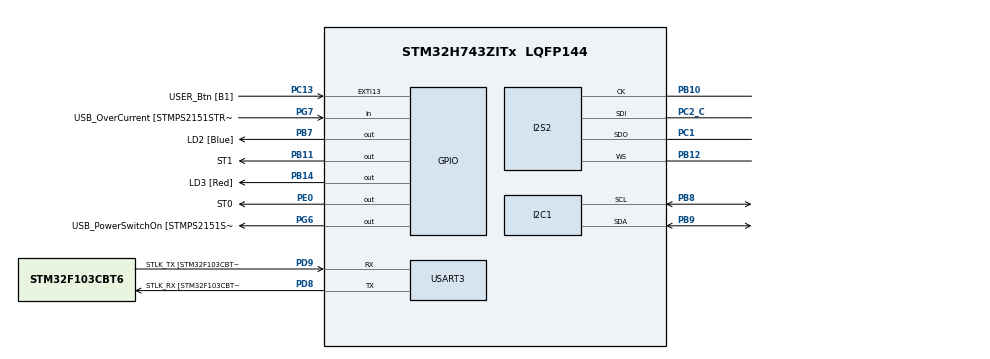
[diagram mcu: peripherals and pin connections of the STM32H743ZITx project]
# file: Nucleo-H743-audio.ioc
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CORTEX_M7.CPU_DCache=Enabled
CORTEX_M7.CPU_ICache=Enabled
Dma.Request0=USART3_RX
Dma.Request1=USART3_TX
Dma.Request2=SPI2_TX
Dma.Request3=SPI2_RX
Dma.SPI2_RX.3.Direction=DMA_PERIPH_TO_MEMORY
Dma.SPI2_RX.3.EventEnable=DISABLE
Dma.SPI2_RX.3.FIFOMode=DMA_FIFOMODE_DISABLE
Dma.SPI2_RX.3.Instance=DMA1_Stream3
Dma.SPI2_RX.3.MemDataAlignment=DMA_MDATAALIGN_WORD
Dma.SPI2_RX.3.MemInc=DMA_MINC_ENABLE
Dma.SPI2_RX.3.Mode=DMA_CIRCULAR
Dma.SPI2_RX.3.PeriphDataAlignment=DMA_PDATAALIGN_WORD
Dma.SPI2_RX.3.PeriphInc=DMA_PINC_DISABLE
Dma.SPI2_RX.3.Polarity=HAL_DMAMUX_REQ_GEN_RISING
Dma.SPI2_RX.3.Priority=DMA_PRIORITY_LOW
Dma.SPI2_RX.3.RequestNumber=1
Dma.SPI2_RX.3.SignalID=NONE
Dma.SPI2_RX.3.SyncEnable=DISABLE
Dma.SPI2_RX.3.SyncPolarity=HAL_DMAMUX_SYNC_NO_EVENT
Dma.SPI2_RX.3.SyncRequestNumber=1
Dma.SPI2_RX.3.SyncSignalID=NONE
Dma.SPI2_TX.2.Direction=DMA_MEMORY_TO_PERIPH
Dma.SPI2_TX.2.EventEnable=DISABLE
Dma.SPI2_TX.2.FIFOMode=DMA_FIFOMODE_DISABLE
Dma.SPI2_TX.2.Instance=DMA1_Stream2
Dma.SPI2_TX.2.MemDataAlignment=DMA_MDATAALIGN_WORD
Dma.SPI2_TX.2.MemInc=DMA_MINC_ENABLE
Dma.SPI2_TX.2.Mode=DMA_NORMAL
Dma.SPI2_TX.2.PeriphDataAlignment=DMA_PDATAALIGN_WORD
Dma.SPI2_TX.2.PeriphInc=DMA_PINC_DISABLE
Dma.SPI2_TX.2.Polarity=HAL_DMAMUX_REQ_GEN_RISING
Dma.SPI2_TX.2.Priority=DMA_PRIORITY_LOW
Dma.SPI2_TX.2.RequestNumber=1
Dma.SPI2_TX.2.SignalID=NONE
Dma.SPI2_TX.2.SyncEnable=DISABLE
Dma.SPI2_TX.2.SyncPolarity=HAL_DMAMUX_SYNC_NO_EVENT
Dma.SPI2_TX.2.SyncRequestNumber=1
Dma.SPI2_TX.2.SyncSignalID=NONE
Dma.USART3_RX.0.Direction=DMA_PERIPH_TO_MEMORY
Dma.USART3_RX.0.EventEnable=DISABLE
Dma.USART3_RX.0.FIFOMode=DMA_FIFOMODE_DISABLE
Dma.USART3_RX.0.Instance=DMA1_Stream0
Dma.USART3_RX.0.MemDataAlignment=DMA_MDATAALIGN_BYTE
Dma.USART3_RX.0.MemInc=DMA_MINC_ENABLE
Dma.USART3_RX.0.Mode=DMA_NORMAL
Dma.USART3_RX.0.PeriphDataAlignment=DMA_PDATAALIGN_BYTE
Dma.USART3_RX.0.PeriphInc=DMA_PINC_DISABLE
Dma.USART3_RX.0.Polarity=HAL_DMAMUX_REQ_GEN_RISING
Dma.USART3_RX.0.Priority=DMA_PRIORITY_LOW
Dma.USART3_RX.0.RequestNumber=1
Dma.USART3_RX.0.SignalID=NONE
Dma.USART3_RX.0.SyncEnable=DISABLE
Dma.USART3_RX.0.SyncPolarity=HAL_DMAMUX_SYNC_NO_EVENT
Dma.USART3_RX.0.SyncRequestNumber=1
Dma.USART3_RX.0.SyncSignalID=NONE
Dma.USART3_TX.1.Direction=DMA_MEMORY_TO_PERIPH
Dma.USART3_TX.1.EventEnable=DISABLE
Dma.USART3_TX.1.FIFOMode=DMA_FIFOMODE_DISABLE
Dma.USART3_TX.1.Instance=DMA1_Stream1
Dma.USART3_TX.1.MemDataAlignment=DMA_MDATAALIGN_BYTE
Dma.USART3_TX.1.MemInc=DMA_MINC_ENABLE
Dma.USART3_TX.1.Mode=DMA_NORMAL
Dma.USART3_TX.1.PeriphDataAlignment=DMA_PDATAALIGN_BYTE
Dma.USART3_TX.1.PeriphInc=DMA_PINC_DISABLE
Dma.USART3_TX.1.Polarity=HAL_DMAMUX_REQ_GEN_RISING
Dma.USART3_TX.1.Priority=DMA_PRIORITY_LOW
Dma.USART3_TX.1.RequestNumber=1
Dma.USART3_TX.1.SignalID=NONE
Dma.USART3_TX.1.SyncEnable=DISABLE
Dma.USART3_TX.1.SyncPolarity=HAL_DMAMUX_SYNC_NO_EVENT
Dma.USART3_TX.1.SyncRequestNumber=1
Dma.USART3_TX.1.SyncSignalID=NONE
FREERTOS.Tasks01=defaultTask,0,256,StartDefaultTask,Default,NULL,Dynamic,NULL,NULL
FREERTOS.configMINIMAL_STACK_SIZE=256
FREERTOS.configTOTAL_HEAP_SIZE=32768
I2C1.Timing=0x307075B1
I2S2.AudioFreq=I2S_AUDIOFREQ_48K
I2S2.DataFormat=I2S_DATAFORMAT_32B
I2S2.ErrorAudioFreq=0.15 %
I2S2.Instance=SPI$Index
I2S2.RealAudioFreq=48.076 KHz
Mcu.Family=STM32H7
Mcu.Name=STM32H743ZITx
Mcu.Package=LQFP144
NVIC.DMA1_Stream0_IRQn=true\:5\:0\:false\:false\:true\:true\:false\:true
NVIC.DMA1_Stream1_IRQn=true\:5\:0\:false\:false\:true\:true\:false\:true
NVIC.DMA1_Stream2_IRQn=true\:5\:0\:false\:false\:true\:true\:false\:true
NVIC.DMA1_Stream3_IRQn=true\:5\:0\:false\:false\:true\:true\:false\:true
NVIC.I2C1_ER_IRQn=true\:5\:0\:false\:false\:true\:true\:true\:true
NVIC.I2C1_EV_IRQn=true\:5\:0\:false\:false\:true\:true\:true\:true
NVIC.PriorityGroup=NVIC_PRIORITYGROUP_4
NVIC.SPI2_IRQn=true\:5\:0\:false\:false\:true\:true\:true\:true
NVIC.TIM17_IRQn=true\:0\:0\:false\:false\:true\:false\:false\:true
NVIC.TimeBase=TIM17_IRQn
NVIC.TimeBaseIP=TIM17
NVIC.USART3_IRQn=true\:5\:0\:false\:false\:true\:true\:true\:true
PB10.Mode=Full_Duplex_Master
PB10.Signal=I2S2_CK
PB11.GPIO_Label=ST1
PB11.Signal=GPIO_Output
PB12.Mode=Full_Duplex_Master
PB12.Signal=I2S2_WS
PB14.GPIO_Label=LD3 [Red]
PB14.Signal=GPIO_Output
PB7.GPIO_Label=LD2 [Blue]
PB7.Signal=GPIO_Output
PB8.Mode=I2C
PB8.Signal=I2C1_SCL
PB9.Mode=I2C
PB9.Signal=I2C1_SDA
PC1.Mode=Full_Duplex_Master
PC1.Signal=I2S2_SDO
PC13.GPIO_Label=USER_Btn [B1]
PC13.Signal=GPXTI13
PC14-OSC32_IN\ (OSC32_IN).Mode=LSE-External-Oscillator
PC14-OSC32_IN\ (OSC32_IN).Signal=RCC_OSC32_IN
PC15-OSC32_OUT\ (OSC32_OUT).Mode=LSE-External-Oscillator
PC15-OSC32_OUT\ (OSC32_OUT).Signal=RCC_OSC32_OUT
PC2_C.Mode=Full_Duplex_Master
PC2_C.Signal=I2S2_SDI
PD8.GPIO_Label=STLK_RX [STM32F103CBT6_PA3]
PD8.Mode=Asynchronous
PD8.Signal=USART3_TX
PD9.GPIO_Label=STLK_TX [STM32F103CBT6_PA2]
PD9.Mode=Asynchronous
PD9.Signal=USART3_RX
PE0.GPIO_Label=ST0
PE0.Signal=GPIO_Output
PG6.GPIO_Label=USB_PowerSwitchOn [STMPS2151STR_EN]
PG6.Signal=GPIO_Output
PG7.GPIO_Label=USB_OverCurrent [STMPS2151STR_FAULT]
PG7.Signal=GPIO_Input
PH0-OSC_IN\ (PH0).GPIO_Label=MCO
PH0-OSC_IN\ (PH0).Mode=HSE-External-Clock-Source
PH0-OSC_IN\ (PH0).Signal=RCC_OSC_IN
PH1-OSC_OUT\ (PH1).Mode=HSE-External-Clock-Source
PH1-OSC_OUT\ (PH1).Signal=RCC_OSC_OUT
ProjectManager.HeapSize=0x200
ProjectManager.StackSize=0x400
ProjectManager.TargetToolchain=STM32CubeIDE
RCC.48MHZClocksFreq_Value=24000000
RCC.ADCFreq_Value=16125000
RCC.AHBFreq_Value=216000000
RCC.APB1CLKDivider=RCC_HCLK_DIV4
RCC.APB1Freq_Value=120000000
RCC.APB1TimFreq_Value=108000000
RCC.APB2CLKDivider=RCC_HCLK_DIV2
RCC.APB2Freq_Value=120000000
RCC.APB2TimFreq_Value=216000000
RCC.APB3Freq_Value=120000000
RCC.APB4Freq_Value=120000000
RCC.CortexFreq_Value=240000000
RCC.D1PPRE=RCC_APB3_DIV2
RCC.D2PPRE1=RCC_APB1_DIV2
RCC.D2PPRE2=RCC_APB2_DIV2
RCC.D3PPRE=RCC_APB4_DIV2
RCC.DIVM1=1
RCC.DIVN1=60
RCC.DIVQ1=4
RCC.HCLKFreq_Value=240000000
RCC.HSE_VALUE=8000000
RCC.HSI_VALUE=64000000
RCC.PLLFRACN=0
RCC.PLLM=25
RCC.PLLMUL=RCC_PLL_MUL9
RCC.PLLN=432
RCC.PLLQ=9
RCC.PLLSourceVirtual=RCC_PLLSOURCE_HSE
RCC.PRESCALERUSB=RCC_USBCLKSOURCE_PLL_DIV1_5
RCC.PWR_Regulator_Voltage_Scale=PWR_REGULATOR_VOLTAGE_SCALE1
RCC.SYSCLKFreq_VALUE=240000000
RCC.SYSCLKSource=RCC_SYSCLKSOURCE_PLLCLK
RCC.SYSCLKSourceVirtual=RCC_SYSCLKSOURCE_PLLCLK
RCC.USBFreq_Value=120000000
RCC.VCOOutputFreq_Value=432000000
USART3.VirtualMode-Asynchronous=VM_ASYNC
VP_FREERTOS_VS_CMSIS_V1.Mode=CMSIS_V1
VP_SYS_VS_tim17.Mode=TIM17
board=NUCLEO-H743ZI

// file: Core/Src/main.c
/* USER CODE BEGIN Header */
/**
 ******************************************************************************
 * @file           : main.c
 * @brief          : Main program body
 ******************************************************************************
 * @attention
 *
 * <h2><center>&copy; Copyright (c) 2020 STMicroelectronics.
 * All rights reserved.</center></h2>
 *
 * This software component is licensed by ST under BSD 3-Clause license,
 * the "License"; You may not use this file except in compliance with the
 * License. You may obtain a copy of the License at:
 *                        opensource.org/licenses/BSD-3-Clause
 *
 ******************************************************************************
 */
/* USER CODE END Header */

#include "main.h"
#include "cmsis_os.h"

/* USER CODE BEGIN Includes */
#include "murasaki_platform.hpp"

/* USER CODE END Includes */

I2C_HandleTypeDef hi2c1;

I2S_HandleTypeDef hi2s2;
DMA_HandleTypeDef hdma_spi2_tx;
DMA_HandleTypeDef hdma_spi2_rx;

UART_HandleTypeDef huart3;
DMA_HandleTypeDef hdma_usart3_rx;
DMA_HandleTypeDef hdma_usart3_tx;

osThreadId defaultTaskHandle;

void SystemClock_Config(void);
static void MX_GPIO_Init(void);
static void MX_DMA_Init(void);
static void MX_USART3_UART_Init(void);
static void MX_I2C1_Init(void);
static void MX_I2S2_Init(void);
void StartDefaultTask(void const * argument);

int main(void)
{

  /* Enable I-Cache---------------------------------------------------------*/
  SCB_EnableICache();

  /* Enable D-Cache---------------------------------------------------------*/
  SCB_EnableDCache();

  /* MCU Configuration--------------------------------------------------------*/

  /* Reset of all peripherals, Initializes the Flash interface and the Systick. */
  HAL_Init();

  /* Configure the system clock */
  SystemClock_Config();

  /* USER CODE BEGIN SysInit */
    __HAL_RCC_SPI1_CLK_ENABLE();
    SET_BIT(SPI1->CFG2, SPI_CFG2_IOSWP);
  /* USER CODE END SysInit */

  /* Initialize all configured peripherals */
  MX_GPIO_Init();
  MX_DMA_Init();
  MX_USART3_UART_Init();
  MX_I2C1_Init();
  MX_I2S2_Init();

  /* Create the thread(s) */
  /* definition and creation of defaultTask */
  osThreadDef(defaultTask, StartDefaultTask, osPriorityNormal, 0, 256);
  defaultTaskHandle = osThreadCreate(osThread(defaultTask), NULL);

  /* Start scheduler */
  osKernelStart();

  /* We should never get here as control is now taken by the scheduler */

  /* Infinite loop */
    while (1)
    {

    }
}

void SystemClock_Config(void)
{
  RCC_OscInitTypeDef RCC_OscInitStruct = {0};
  RCC_ClkInitTypeDef RCC_ClkInitStruct = {0};
  RCC_PeriphCLKInitTypeDef PeriphClkInitStruct = {0};

  /** Supply configuration update enable
  */
  HAL_PWREx_ConfigSupply(PWR_LDO_SUPPLY);
  /** Configure the main internal regulator output voltage
  */
  __HAL_PWR_VOLTAGESCALING_CONFIG(PWR_REGULATOR_VOLTAGE_SCALE1);

  while(!__HAL_PWR_GET_FLAG(PWR_FLAG_VOSRDY)) {}
  /** Initializes the CPU, AHB and APB busses clocks
  */
  RCC_OscInitStruct.OscillatorType = RCC_OSCILLATORTYPE_HSE;
  RCC_OscInitStruct.HSEState = RCC_HSE_BYPASS;
  RCC_OscInitStruct.PLL.PLLState = RCC_PLL_ON;
  RCC_OscInitStruct.PLL.PLLSource = RCC_PLLSOURCE_HSE;
  RCC_OscInitStruct.PLL.PLLM = 1;
  RCC_OscInitStruct.PLL.PLLN = 60;
  RCC_OscInitStruct.PLL.PLLP = 2;
  RCC_OscInitStruct.PLL.PLLQ = 4;
  RCC_OscInitStruct.PLL.PLLR = 2;
  RCC_OscInitStruct.PLL.PLLRGE = RCC_PLL1VCIRANGE_3;
  RCC_OscInitStruct.PLL.PLLVCOSEL = RCC_PLL1VCOWIDE;
  RCC_OscInitStruct.PLL.PLLFRACN = 0;
  if (HAL_RCC_OscConfig(&RCC_OscInitStruct) != HAL_OK)
  {
    Error_Handler();
  }
  /** Initializes the CPU, AHB and APB busses clocks
  */
  RCC_ClkInitStruct.ClockType = RCC_CLOCKTYPE_HCLK|RCC_CLOCKTYPE_SYSCLK
                              |RCC_CLOCKTYPE_PCLK1|RCC_CLOCKTYPE_PCLK2
                              |RCC_CLOCKTYPE_D3PCLK1|RCC_CLOCKTYPE_D1PCLK1;
  RCC_ClkInitStruct.SYSCLKSource = RCC_SYSCLKSOURCE_PLLCLK;
  RCC_ClkInitStruct.SYSCLKDivider = RCC_SYSCLK_DIV1;
  RCC_ClkInitStruct.AHBCLKDivider = RCC_HCLK_DIV1;
  RCC_ClkInitStruct.APB3CLKDivider = RCC_APB3_DIV2;
  RCC_ClkInitStruct.APB1CLKDivider = RCC_APB1_DIV2;
  RCC_ClkInitStruct.APB2CLKDivider = RCC_APB2_DIV2;
  RCC_ClkInitStruct.APB4CLKDivider = RCC_APB4_DIV2;

  if (HAL_RCC_ClockConfig(&RCC_ClkInitStruct, FLASH_LATENCY_4) != HAL_OK)
  {
    Error_Handler();
  }
  PeriphClkInitStruct.PeriphClockSelection = RCC_PERIPHCLK_USART3|RCC_PERIPHCLK_SPI2
                              |RCC_PERIPHCLK_I2C1;
  PeriphClkInitStruct.Spi123ClockSelection = RCC_SPI123CLKSOURCE_PLL;
  PeriphClkInitStruct.Usart234578ClockSelection = RCC_USART234578CLKSOURCE_D2PCLK1;
  PeriphClkInitStruct.I2c123ClockSelection = RCC_I2C123CLKSOURCE_D2PCLK1;
  if (HAL_RCCEx_PeriphCLKConfig(&PeriphClkInitStruct) != HAL_OK)
  {
    Error_Handler();
  }
}

static void MX_I2C1_Init(void)
{

  hi2c1.Instance = I2C1;
  hi2c1.Init.Timing = 0x307075B1;
  hi2c1.Init.OwnAddress1 = 0;
  hi2c1.Init.AddressingMode = I2C_ADDRESSINGMODE_7BIT;
  hi2c1.Init.DualAddressMode = I2C_DUALADDRESS_DISABLE;
  hi2c1.Init.OwnAddress2 = 0;
  hi2c1.Init.OwnAddress2Masks = I2C_OA2_NOMASK;
  hi2c1.Init.GeneralCallMode = I2C_GENERALCALL_DISABLE;
  hi2c1.Init.NoStretchMode = I2C_NOSTRETCH_DISABLE;
  if (HAL_I2C_Init(&hi2c1) != HAL_OK)
  {
    Error_Handler();
  }
  /** Configure Analogue filter
  */
  if (HAL_I2CEx_ConfigAnalogFilter(&hi2c1, I2C_ANALOGFILTER_ENABLE) != HAL_OK)
  {
    Error_Handler();
  }
  /** Configure Digital filter
  */
  if (HAL_I2CEx_ConfigDigitalFilter(&hi2c1, 0) != HAL_OK)
  {
    Error_Handler();
  }

}

static void MX_I2S2_Init(void)
{

  hi2s2.Instance = SPI2;
  hi2s2.Init.Mode = I2S_MODE_MASTER_FULLDUPLEX;
  hi2s2.Init.Standard = I2S_STANDARD_PHILIPS;
  hi2s2.Init.DataFormat = I2S_DATAFORMAT_32B;
  hi2s2.Init.MCLKOutput = I2S_MCLKOUTPUT_DISABLE;
  hi2s2.Init.AudioFreq = I2S_AUDIOFREQ_48K;
  hi2s2.Init.CPOL = I2S_CPOL_LOW;
  hi2s2.Init.FirstBit = I2S_FIRSTBIT_MSB;
  hi2s2.Init.WSInversion = I2S_WS_INVERSION_DISABLE;
  hi2s2.Init.Data24BitAlignment = I2S_DATA_24BIT_ALIGNMENT_RIGHT;
  hi2s2.Init.MasterKeepIOState = I2S_MASTER_KEEP_IO_STATE_DISABLE;
  if (HAL_I2S_Init(&hi2s2) != HAL_OK)
  {
    Error_Handler();
  }

}

static void MX_USART3_UART_Init(void)
{

  huart3.Instance = USART3;
  huart3.Init.BaudRate = 115200;
  huart3.Init.WordLength = UART_WORDLENGTH_8B;
  huart3.Init.StopBits = UART_STOPBITS_1;
  huart3.Init.Parity = UART_PARITY_NONE;
  huart3.Init.Mode = UART_MODE_TX_RX;
  huart3.Init.HwFlowCtl = UART_HWCONTROL_NONE;
  huart3.Init.OverSampling = UART_OVERSAMPLING_16;
  huart3.Init.OneBitSampling = UART_ONE_BIT_SAMPLE_DISABLE;
  huart3.Init.ClockPrescaler = UART_PRESCALER_DIV1;
  huart3.AdvancedInit.AdvFeatureInit = UART_ADVFEATURE_NO_INIT;
  if (HAL_UART_Init(&huart3) != HAL_OK)
  {
    Error_Handler();
  }
  if (HAL_UARTEx_SetTxFifoThreshold(&huart3, UART_TXFIFO_THRESHOLD_1_8) != HAL_OK)
  {
    Error_Handler();
  }
  if (HAL_UARTEx_SetRxFifoThreshold(&huart3, UART_RXFIFO_THRESHOLD_1_8) != HAL_OK)
  {
    Error_Handler();
  }
  if (HAL_UARTEx_DisableFifoMode(&huart3) != HAL_OK)
  {
    Error_Handler();
  }

}

static void MX_DMA_Init(void)
{

  /* DMA controller clock enable */
  __HAL_RCC_DMA1_CLK_ENABLE();

  /* DMA interrupt init */
  /* DMA1_Stream0_IRQn interrupt configuration */
  HAL_NVIC_SetPriority(DMA1_Stream0_IRQn, 5, 0);
  HAL_NVIC_EnableIRQ(DMA1_Stream0_IRQn);
  /* DMA1_Stream1_IRQn interrupt configuration */
  HAL_NVIC_SetPriority(DMA1_Stream1_IRQn, 5, 0);
  HAL_NVIC_EnableIRQ(DMA1_Stream1_IRQn);
  /* DMA1_Stream2_IRQn interrupt configuration */
  HAL_NVIC_SetPriority(DMA1_Stream2_IRQn, 5, 0);
  HAL_NVIC_EnableIRQ(DMA1_Stream2_IRQn);
  /* DMA1_Stream3_IRQn interrupt configuration */
  HAL_NVIC_SetPriority(DMA1_Stream3_IRQn, 5, 0);
  HAL_NVIC_EnableIRQ(DMA1_Stream3_IRQn);

}

static void MX_GPIO_Init(void)
{
  GPIO_InitTypeDef GPIO_InitStruct = {0};

  /* GPIO Ports Clock Enable */
  __HAL_RCC_GPIOE_CLK_ENABLE();
  __HAL_RCC_GPIOC_CLK_ENABLE();
  __HAL_RCC_GPIOF_CLK_ENABLE();
  __HAL_RCC_GPIOH_CLK_ENABLE();
  __HAL_RCC_GPIOA_CLK_ENABLE();
  __HAL_RCC_GPIOB_CLK_ENABLE();
  __HAL_RCC_GPIOG_CLK_ENABLE();
  __HAL_RCC_GPIOD_CLK_ENABLE();

  /*Configure GPIO pin Output Level */
  HAL_GPIO_WritePin(GPIOB, ST1_Pin|LD3_Pin|LD2_Pin, GPIO_PIN_RESET);

  /*Configure GPIO pin Output Level */
  HAL_GPIO_WritePin(USB_PowerSwitchOn_GPIO_Port, USB_PowerSwitchOn_Pin, GPIO_PIN_RESET);

  /*Configure GPIO pin Output Level */
  HAL_GPIO_WritePin(ST0_GPIO_Port, ST0_Pin, GPIO_PIN_RESET);

  /*Configure GPIO pins : PE2 PE3 PE4 PE5
                           PE6 PE7 PE8 PE9
                           PE10 PE11 PE12 PE13
                           PE14 PE15 PE1 */
  GPIO_InitStruct.Pin = GPIO_PIN_2|GPIO_PIN_3|GPIO_PIN_4|GPIO_PIN_5
                          |GPIO_PIN_6|GPIO_PIN_7|GPIO_PIN_8|GPIO_PIN_9
                          |GPIO_PIN_10|GPIO_PIN_11|GPIO_PIN_12|GPIO_PIN_13
                          |GPIO_PIN_14|GPIO_PIN_15|GPIO_PIN_1;
  GPIO_InitStruct.Mode = GPIO_MODE_ANALOG;
  GPIO_InitStruct.Pull = GPIO_NOPULL;
  HAL_GPIO_Init(GPIOE, &GPIO_InitStruct);

  /*Configure GPIO pin : USER_Btn_Pin */
  GPIO_InitStruct.Pin = USER_Btn_Pin;
  GPIO_InitStruct.Mode = GPIO_MODE_IT_RISING;
  GPIO_InitStruct.Pull = GPIO_NOPULL;
  HAL_GPIO_Init(USER_Btn_GPIO_Port, &GPIO_InitStruct);

  /*Configure GPIO pins : PF0 PF1 PF2 PF3
                           PF4 PF5 PF6 PF7
                           PF8 PF9 PF10 PF11
                           PF12 PF13 PF14 PF15 */
  GPIO_InitStruct.Pin = GPIO_PIN_0|GPIO_PIN_1|GPIO_PIN_2|GPIO_PIN_3
                          |GPIO_PIN_4|GPIO_PIN_5|GPIO_PIN_6|GPIO_PIN_7
                          |GPIO_PIN_8|GPIO_PIN_9|GPIO_PIN_10|GPIO_PIN_11
                          |GPIO_PIN_12|GPIO_PIN_13|GPIO_PIN_14|GPIO_PIN_15;
  GPIO_InitStruct.Mode = GPIO_MODE_ANALOG;
  GPIO_InitStruct.Pull = GPIO_NOPULL;
  HAL_GPIO_Init(GPIOF, &GPIO_InitStruct);

  /*Configure GPIO pins : PC0 PC3 PC4 PC5
                           PC6 PC7 PC8 PC9
                           PC10 PC11 PC12 */
  GPIO_InitStruct.Pin = GPIO_PIN_0|GPIO_PIN_3|GPIO_PIN_4|GPIO_PIN_5
                          |GPIO_PIN_6|GPIO_PIN_7|GPIO_PIN_8|GPIO_PIN_9
                          |GPIO_PIN_10|GPIO_PIN_11|GPIO_PIN_12;
  GPIO_InitStruct.Mode = GPIO_MODE_ANALOG;
  GPIO_InitStruct.Pull = GPIO_NOPULL;
  HAL_GPIO_Init(GPIOC, &GPIO_InitStruct);

  /*Configure GPIO pins : PA0 PA1 PA2 PA3
                           PA4 PA5 PA6 PA7
                           PA8 PA9 PA10 PA11
                           PA12 PA13 PA14 PA15 */
  GPIO_InitStruct.Pin = GPIO_PIN_0|GPIO_PIN_1|GPIO_PIN_2|GPIO_PIN_3
                          |GPIO_PIN_4|GPIO_PIN_5|GPIO_PIN_6|GPIO_PIN_7
                          |GPIO_PIN_8|GPIO_PIN_9|GPIO_PIN_10|GPIO_PIN_11
                          |GPIO_PIN_12|GPIO_PIN_13|GPIO_PIN_14|GPIO_PIN_15;
  GPIO_InitStruct.Mode = GPIO_MODE_ANALOG;
  GPIO_InitStruct.Pull = GPIO_NOPULL;
  HAL_GPIO_Init(GPIOA, &GPIO_InitStruct);

  /*Configure GPIO pins : PB0 PB1 PB2 PB13
                           PB15 PB3 PB4 PB5
                           PB6 */
  GPIO_InitStruct.Pin = GPIO_PIN_0|GPIO_PIN_1|GPIO_PIN_2|GPIO_PIN_13
                          |GPIO_PIN_15|GPIO_PIN_3|GPIO_PIN_4|GPIO_PIN_5
                          |GPIO_PIN_6;
  GPIO_InitStruct.Mode = GPIO_MODE_ANALOG;
  GPIO_InitStruct.Pull = GPIO_NOPULL;
  HAL_GPIO_Init(GPIOB, &GPIO_InitStruct);

  /*Configure GPIO pins : PG0 PG1 PG2 PG3
                           PG4 PG5 PG8 PG9
                           PG10 PG11 PG12 PG13
                           PG14 PG15 */
  GPIO_InitStruct.Pin = GPIO_PIN_0|GPIO_PIN_1|GPIO_PIN_2|GPIO_PIN_3
                          |GPIO_PIN_4|GPIO_PIN_5|GPIO_PIN_8|GPIO_PIN_9
                          |GPIO_PIN_10|GPIO_PIN_11|GPIO_PIN_12|GPIO_PIN_13
                          |GPIO_PIN_14|GPIO_PIN_15;
  GPIO_InitStruct.Mode = GPIO_MODE_ANALOG;
  GPIO_InitStruct.Pull = GPIO_NOPULL;
  HAL_GPIO_Init(GPIOG, &GPIO_InitStruct);

  /*Configure GPIO pins : ST1_Pin LD3_Pin LD2_Pin */
  GPIO_InitStruct.Pin = ST1_Pin|LD3_Pin|LD2_Pin;
  GPIO_InitStruct.Mode = GPIO_MODE_OUTPUT_PP;
  GPIO_InitStruct.Pull = GPIO_NOPULL;
  GPIO_InitStruct.Speed = GPIO_SPEED_FREQ_LOW;
  HAL_GPIO_Init(GPIOB, &GPIO_InitStruct);

  /*Configure GPIO pins : PD10 PD11 PD12 PD13
                           PD14 PD15 PD0 PD1
                           PD2 PD3 PD4 PD5
                           PD6 PD7 */
  GPIO_InitStruct.Pin = GPIO_PIN_10|GPIO_PIN_11|GPIO_PIN_12|GPIO_PIN_13
                          |GPIO_PIN_14|GPIO_PIN_15|GPIO_PIN_0|GPIO_PIN_1
                          |GPIO_PIN_2|GPIO_PIN_3|GPIO_PIN_4|GPIO_PIN_5
                          |GPIO_PIN_6|GPIO_PIN_7;
  GPIO_InitStruct.Mode = GPIO_MODE_ANALOG;
  GPIO_InitStruct.Pull = GPIO_NOPULL;
  HAL_GPIO_Init(GPIOD, &GPIO_InitStruct);

  /*Configure GPIO pin : USB_PowerSwitchOn_Pin */
  GPIO_InitStruct.Pin = USB_PowerSwitchOn_Pin;
  GPIO_InitStruct.Mode = GPIO_MODE_OUTPUT_PP;
  GPIO_InitStruct.Pull = GPIO_NOPULL;
  GPIO_InitStruct.Speed = GPIO_SPEED_FREQ_LOW;
  HAL_GPIO_Init(USB_PowerSwitchOn_GPIO_Port, &GPIO_InitStruct);

  /*Configure GPIO pin : USB_OverCurrent_Pin */
  GPIO_InitStruct.Pin = USB_OverCurrent_Pin;
  GPIO_InitStruct.Mode = GPIO_MODE_INPUT;
  GPIO_InitStruct.Pull = GPIO_NOPULL;
  HAL_GPIO_Init(USB_OverCurrent_GPIO_Port, &GPIO_InitStruct);

  /*Configure GPIO pin : ST0_Pin */
  GPIO_InitStruct.Pin = ST0_Pin;
  GPIO_InitStruct.Mode = GPIO_MODE_OUTPUT_PP;
  GPIO_InitStruct.Pull = GPIO_NOPULL;
  GPIO_InitStruct.Speed = GPIO_SPEED_FREQ_LOW;
  HAL_GPIO_Init(ST0_GPIO_Port, &GPIO_InitStruct);

}

void StartDefaultTask(void const * argument)
{
  /* USER CODE BEGIN 5 */
    InitPlatform();
    ExecPlatform();
    /* Infinite loop */
    for (;;)
            {
        osDelay(1);
    }
  /* USER CODE END 5 */
}

void HAL_TIM_PeriodElapsedCallback(TIM_HandleTypeDef *htim)
{
  if (htim->Instance == TIM17) {
    HAL_IncTick();
  }
}

void Error_Handler(void)
{
}

#ifdef  USE_FULL_ASSERT
/**
  * @brief  Reports the name of the source file and the source line number
  *         where the assert_param error has occurred.
  * @param  file: pointer to the source file name
  * @param  line: assert_param error line source number
  * @retval None
  */
void assert_failed(uint8_t *file, uint32_t line)
{
  /* USER CODE BEGIN 6 */
    /* User can add his own implementation to report the file name and line number,
     tex: printf("Wrong parameters value: file %s on line %d\r\n", file, line) */
    CustomAssertFailed(file, line);
  /* USER CODE END 6 */
}
#endif /* USE_FULL_ASSERT */

/************************ (C) COPYRIGHT STMicroelectronics *****END OF FILE****/
